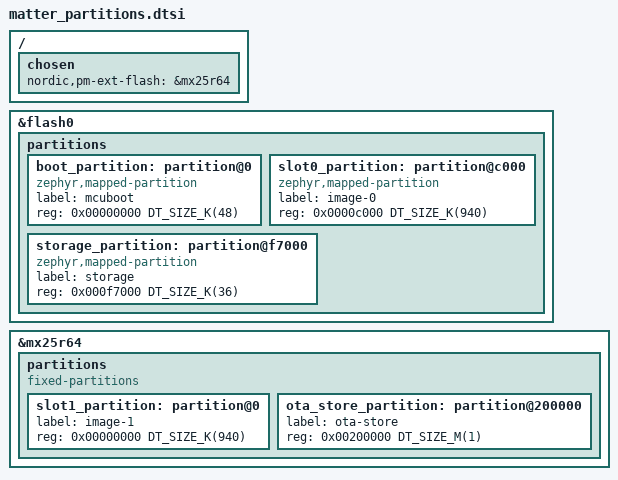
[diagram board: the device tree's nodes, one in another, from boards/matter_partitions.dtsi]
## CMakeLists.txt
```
#
# Cranium firmware, Matter variant: the board as Matter commissioner and Thread border router
# (docs/matter-thread.md). A separate application from firmware/app, with the same version number: VERSION
# here is a link to firmware/app/VERSION.
#
# The Matter commissioner is this project's own (src/matter/): connectedhomeip's controller does not fit next to
# Wi-Fi and the border router in the nRF5340's flash.
#
cmake_minimum_required(VERSION 3.20.0)

find_package(Zephyr REQUIRED HINTS $ENV{ZEPHYR_BASE})
project(cranium_matter)

target_sources(app PRIVATE
  src/main.c
  src/ot_leader.c
  src/matter_shell.c
  src/policy/matter_policy.c
  src/matter/mt_tlv.c
  src/matter/mt_btp.c
  src/matter/mt_msg.c
  src/matter/mt_im.c
  src/matter/mt_pase_msg.c
  src/matter/mt_crypto.c
  src/matter/mt_ble.c
  src/matter/mt_ble_adv.c
  src/matter/mt_commission.c
  src/matter/mt_der.c
  src/matter/mt_cert.c
  src/matter/mt_attest.c
  src/matter/mt_test_paa.c
  src/matter/mt_fabric.c
  src/matter/mt_case_msg.c
  src/matter/mt_controller.c
  src/matter/mt_bdx.c
  src/matter/mt_ota.c
  src/matter/mt_ota_store.c
  src/matter/mt_server.c
  src/matter/mt_identity.c
  src/matter/mt_node.c
  src/matter/mt_csr.c
  src/matter/mt_dev_im.c
  src/matter/mt_peripheral.c
  src/matter/mt_ota_req.c
  src/matter_node.c
  src/matter_selftest.c
)
target_include_directories(app PRIVATE src src/policy src/matter)

# The board's Matter TEST device credentials (DAC, its key, PAI, certification declaration), generated from the
# Matter SDK in the build's SDK at configure time, so that no key is kept in this repository.
set(cranium_test_creds ${CMAKE_CURRENT_BINARY_DIR}/mt_test_credentials.c)
find_package(Python3 REQUIRED COMPONENTS Interpreter)
execute_process(
  COMMAND ${Python3_EXECUTABLE} -I ${CMAKE_CURRENT_LIST_DIR}/scripts/gen_test_credentials.py
          ${ZEPHYR_CONNECTEDHOMEIP_MODULE_DIR} ${cranium_test_creds}
  RESULT_VARIABLE cranium_creds_result)
if(NOT cranium_creds_result EQUAL 0)
  message(FATAL_ERROR "The Matter SDK's test credentials could not be read (scripts/gen_test_credentials.py)")
endif()
target_sources(app PRIVATE ${cranium_test_creds})

if(CONFIG_CRANIUM_MATTER_BORDER_ROUTER)
  target_sources(app PRIVATE src/border_router.c)

  # The border router's platform code for OpenThread: the backbone interface, the UDP and mDNS sockets.
  # Zephyr has it in modules/openthread/platform, but this SDK builds OpenThread's platform from its own list
  # (nrf/modules/openthread/platform), which leaves these out, so this application builds them, patched for this
  # SDK's OpenThread (sdk/patch_sdk.py). src/br/br_unused.c stands in for the parts left out.
  set(ot_platform ${ZEPHYR_BASE}/modules/openthread/platform)
  target_sources(app PRIVATE
    ${ot_platform}/infra_if.c
    ${ot_platform}/udp.c
    ${ot_platform}/mdns_socket.c
    src/br/br_unused.c
  )
  target_include_directories(app PRIVATE
    ${ot_platform}
    ${ZEPHYR_BASE}/subsys/net/ip
    ${ZEPHYR_BASE}/subsys/net/lib/sockets
    ${ZEPHYR_BASE}/subsys/net/lib/dns
    ${ZEPHYR_OPENTHREAD_MODULE_DIR}/src/core
  )
  target_link_libraries(app PRIVATE ot-config)
  # Zephyr's OpenThread start-up code includes the border router's header from here.
  zephyr_include_directories(${ZEPHYR_BASE}/subsys/net/l2/openthread ${ot_platform})
endif()
```

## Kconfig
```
#
# The Matter variant: the board as Matter commissioner and Thread border router (docs/matter-thread.md).
#
mainmenu "Cranium Matter commissioner and Thread border router"

config CRANIUM_THREAD_CHANNEL
	int "Thread channel of a network this board forms"
	range 11 26
	default 25
	help
	  Used only when the board has no Thread network yet and forms one. Keep it away from the Wi-Fi channel:
	  25 is clear of Wi-Fi 1 and 6, 15 of Wi-Fi 11 (src/policy/matter_policy.c, mp_pick_thread_channel()).

config CRANIUM_MATTER_BORDER_ROUTER
	bool "Thread border router with Wi-Fi as the backbone"
	default y if WIFI_NRF70
	depends on OPENTHREAD_ZEPHYR_BORDER_ROUTER
	help
	  Joins the stored Wi-Fi network at start-up (src/border_router.c); Zephyr's OpenThread border router
	  takes it as the backbone once it is up. Wi-Fi credentials are added with the shell's "wifi cred add".

source "Kconfig.zephyr"
```

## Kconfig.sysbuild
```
#
# Sysbuild for the Matter variant: MCUboot, and the network core running Bluetooth and 802.15.4 together.
#

choice BOOTLOADER
	default BOOTLOADER_MCUBOOT
endchoice

config NRF_DEFAULT_IPC_RADIO
	default y

config NETCORE_IPC_RADIO_IEEE802154
	default y

config NETCORE_IPC_RADIO_BT_HCI_IPC
	default y

# The Wi-Fi chip, on the nRF7002 DK only: the border router's backbone.
config WIFI_NRF70
	default y if BOARD_NRF7002DK

config PARTITION_MANAGER
	default n

source "share/sysbuild/Kconfig"
```

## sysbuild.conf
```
#
# Sysbuild settings of the Matter variant (docs/matter-thread.md).
#
SB_CONFIG_MATTER=y
SB_CONFIG_PARTITION_MANAGER=n
SB_CONFIG_BOOTLOADER_MCUBOOT=y
# The team's signing key, as in firmware/app/sysbuild.conf; it stays outside the repository.
SB_CONFIG_BOOT_SIGNATURE_TYPE_ECDSA_P256=y
SB_CONFIG_BOOT_SIGNATURE_KEY_FILE="\$ENV{HOME}/.cranium/mcuboot_signing_key.pem"
SB_CONFIG_MCUBOOT_MODE_SWAP_USING_MOVE=y
# The application image only; the network core is flashed over the debug port.
SB_CONFIG_SECURE_BOOT_NETCORE=n
SB_CONFIG_NETCORE_APP_UPDATE=n
```

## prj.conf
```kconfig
#
# The Matter variant, common to both boards (docs/matter-thread.md). border_router.conf adds Wi-Fi and the
# border router on the nRF7002 DK. The Matter commissioner is this project's own C code (src/matter/), built on
# the PSA crypto API: no connectedhomeip, no mbedTLS X.509.
#

# Bluetooth LE: central for commissioning (BTP over the device's CHIPoBLE service), peripheral for updates.
CONFIG_BT=y
CONFIG_BT_CENTRAL=y
CONFIG_BT_OBSERVER=y
CONFIG_BT_PERIPHERAL=y
CONFIG_BT_GATT_CLIENT=y
CONFIG_BT_GATT_AUTO_DISCOVER_CCC=y
CONFIG_BT_MAX_CONN=2
CONFIG_BT_BUF_ACL_RX_SIZE=251
CONFIG_BT_BUF_ACL_TX_SIZE=251
CONFIG_BT_L2CAP_TX_MTU=247
CONFIG_BT_DEVICE_NAME="Cranium"

# Thread: a full device that forms the network and leads it, with the SRP and DNS-SD server the devices
# register with. OpenThread's heap is the system heap: on its own small one the SRP server starts with no
# domain and refuses every registration.
CONFIG_NETWORKING=y
CONFIG_NET_L2_OPENTHREAD=y
CONFIG_OPENTHREAD_FTD=y
CONFIG_OPENTHREAD_MANUAL_START=y
CONFIG_OPENTHREAD_EXTERNAL_HEAP=y
CONFIG_OPENTHREAD_SRP_SERVER=y
CONFIG_OPENTHREAD_ENABLE_SERVICE=y
CONFIG_OPENTHREAD_DNSSD_SERVER=y
CONFIG_OPENTHREAD_DNS_CLIENT=y
CONFIG_OPENTHREAD_MAX_CHILDREN=10
CONFIG_NET_IPV6=y
CONFIG_NET_UDP=y
CONFIG_NET_SOCKETS=y

# Crypto for the commissioner, through PSA: SPAKE2+ as the prover (PASE), P-256 ECDSA and ECDH (CASE, the
# fabric's certificates, attestation), HKDF, AES-CCM, PBKDF2 and SHA-256.
CONFIG_PSA_CRYPTO_DRIVER_OBERON=y
CONFIG_PSA_WANT_ALG_SPAKE2P_MATTER=y
CONFIG_PSA_WANT_KEY_TYPE_SPAKE2P_KEY_PAIR_IMPORT=y
CONFIG_PSA_WANT_ALG_ECDSA=y
CONFIG_PSA_WANT_ALG_ECDH=y
CONFIG_PSA_WANT_ECC_SECP_R1_256=y
CONFIG_PSA_WANT_KEY_TYPE_ECC_KEY_PAIR_GENERATE=y
CONFIG_PSA_WANT_KEY_TYPE_ECC_KEY_PAIR_IMPORT=y
CONFIG_PSA_WANT_KEY_TYPE_ECC_KEY_PAIR_EXPORT=y
CONFIG_PSA_WANT_KEY_TYPE_ECC_PUBLIC_KEY=y
CONFIG_PSA_WANT_ALG_HKDF=y
CONFIG_PSA_WANT_ALG_HMAC=y
CONFIG_PSA_WANT_ALG_CCM=y
CONFIG_PSA_WANT_KEY_TYPE_AES=y
CONFIG_PSA_WANT_ALG_PBKDF2_HMAC=y
CONFIG_PSA_WANT_ALG_SHA_256=y
# This board as a device: the PASE verifier (w0 || L from the passcode).
CONFIG_PSA_WANT_KEY_TYPE_SPAKE2P_PUBLIC_KEY=y
CONFIG_PSA_WANT_KEY_TYPE_SPAKE2P_KEY_PAIR_DERIVE=y
CONFIG_PSA_WANT_KEY_TYPE_SPAKE2P_KEY_PAIR_EXPORT=y

# Its own update over Matter: the image goes into MCUboot's second slot.
CONFIG_FLASH_PAGE_LAYOUT=y
CONFIG_STREAM_FLASH=y
CONFIG_IMG_MANAGER=y
CONFIG_MCUBOOT_IMG_MANAGER=y

# The fabric's root key and the board's operational key are persistent PSA keys, kept by trusted storage in
# settings. Without a hardware unique key in use, their storage key comes from a hash of the key ID: not
# protected against someone reading the flash.
CONFIG_MBEDTLS_PSA_CRYPTO_STORAGE_C=y
CONFIG_TRUSTED_STORAGE=y
CONFIG_TRUSTED_STORAGE_BACKEND_AEAD_KEY_HASH_UID=y
CONFIG_TRUSTED_STORAGE_STORAGE_BACKEND_SETTINGS=y

# Storage, console and shell.
CONFIG_SETTINGS=y
CONFIG_SETTINGS_NVS=y
CONFIG_FLASH=y
CONFIG_FLASH_MAP=y
CONFIG_NVS=y
CONFIG_SHELL=y
# Long enough for tools/matter_ota_upload.py's chunks of an OTA image.
CONFIG_SHELL_CMD_BUFF_SIZE=600
CONFIG_LOG=y
# Warnings and errors only from the stacks; this project's modules log their own progress.
CONFIG_LOG_DEFAULT_LEVEL=2
CONFIG_MAIN_STACK_SIZE=4096
CONFIG_SYSTEM_WORKQUEUE_STACK_SIZE=4096
CONFIG_HEAP_MEM_POOL_SIZE=32768
CONFIG_REBOOT=y
CONFIG_THREAD_NAME=y
CONFIG_MPU_STACK_GUARD=y
CONFIG_DK_LIBRARY=y
```

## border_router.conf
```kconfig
#
# The border router: Wi-Fi station on the nRF7002 DK, and Zephyr's OpenThread border router with Wi-Fi as its
# backbone. Added to the application by sysbuild.cmake when SB_CONFIG_CRANIUM_BORDER_ROUTER is on
# (border_router_sysbuild.conf). Matter itself stays on Thread (CHIP_WIFI off): Wi-Fi is the border router's link,
# not a Matter transport.
#
# It does not fit yet: docs/matter-thread.md, "Memory, per board".
#
CONFIG_CHIP_WIFI=n
CONFIG_WIFI=y
CONFIG_WIFI_NRF70=y
CONFIG_WIFI_NM_WPA_SUPPLICANT=y
CONFIG_NET_L2_ETHERNET=y
CONFIG_WIFI_CREDENTIALS=y
CONFIG_WIFI_CREDENTIALS_SHELL=y
CONFIG_NET_L2_WIFI_SHELL=y

# IP on both sides, routing between them.
CONFIG_NET_IPV6=y
CONFIG_NET_IPV4=y
CONFIG_NET_UDP=y
CONFIG_NET_TCP=y
CONFIG_NET_SOCKETS=y
CONFIG_NET_DHCPV4=y
CONFIG_NET_MGMT_EVENT=y
CONFIG_NET_MGMT_EVENT_INFO=y
CONFIG_NET_CONNECTION_MANAGER=y
CONFIG_NET_ROUTE_MCAST=y
CONFIG_NET_SOCKETS_SERVICE=y
CONFIG_NET_CONTEXT_RECV_PKTINFO=y
CONFIG_NET_CONTEXT_RECV_HOPLIMIT=y
CONFIG_NET_IPV6_NBR_CACHE=y
CONFIG_NET_MAX_MCAST_ROUTES=10
CONFIG_NET_SOCKETS_INET_RAW=y

# Zephyr's OpenThread border router, cut to what a home network needs: routing between Thread and Wi-Fi, the SRP
# advertising proxy with mDNS on Wi-Fi (a laptop finds the Matter devices), and the border agent, which Zephyr's
# border router code requires. Left out to save memory: NAT64, TREL, DHCPv6 prefix delegation, upstream DNS.
CONFIG_OPENTHREAD_ZEPHYR_BORDER_ROUTER=y
CONFIG_OPENTHREAD_ZEPHYR_BORDER_ROUTER_VENDOR_NAME="Cranium"
CONFIG_OPENTHREAD_ZEPHYR_BORDER_ROUTER_BASE_SERVICE_NAME="Cranium-BorderRouter"
CONFIG_OPENTHREAD_ZEPHYR_BORDER_ROUTER_MODEL_NAME="Cranium"
CONFIG_OPENTHREAD_ZEPHYR_BORDER_ROUTER_IPV4=n
CONFIG_OPENTHREAD_ZEPHYR_BORDER_ROUTER_NAT64_TRANSLATOR=n
CONFIG_OPENTHREAD_BORDER_ROUTER=y
CONFIG_OPENTHREAD_BORDER_ROUTING=y
# Needed by OpenThread's routing manager in this SDK, which does not build without it.
CONFIG_OPENTHREAD_BORDER_ROUTING_COUNTERS=y
CONFIG_OPENTHREAD_BORDER_AGENT=y
CONFIG_OPENTHREAD_BORDER_AGENT_ID=y
CONFIG_OPENTHREAD_BORDER_AGENT_MESHCOP_SERVICE=y
# The border agent's DTLS with EC-JPAKE comes with OpenThread's own (Thread-level) commissioner, as in Zephyr's
# border router sample; it also lets the border router admit Thread joiners.
CONFIG_OPENTHREAD_COMMISSIONER=y
CONFIG_OPENTHREAD_NETDATA_PUBLISHER=y
CONFIG_OPENTHREAD_BACKBONE_ROUTER=y
CONFIG_OPENTHREAD_BACKBONE_ROUTER_MULTICAST_ROUTING=y
CONFIG_OPENTHREAD_SRP_ADV_PROXY=y
CONFIG_OPENTHREAD_DNSSD_DISCOVERY_PROXY=y
CONFIG_OPENTHREAD_MULTICAST_DNS=y
CONFIG_OPENTHREAD_PLATFORM_UDP=y
CONFIG_OPENTHREAD_INTERFACE_EARLY_UP=y
CONFIG_OPENTHREAD_SLAAC=y
CONFIG_OPENTHREAD_MAX_STATECHANGE_HANDLERS=3
CONFIG_OPENTHREAD_DUA=y
CONFIG_OPENTHREAD_MLR=y
CONFIG_OPENTHREAD_IP6_FRAGM=y
CONFIG_OPENTHREAD_ECDSA=y
CONFIG_OPENTHREAD_TREL=n
CONFIG_OPENTHREAD_NAT64_TRANSLATOR=n

# Room in flash: the supplicant logs errors only and leaves out WEP, which no network should still use.
CONFIG_WIFI_NM_WPA_SUPPLICANT_LOG_LEVEL_ERR=y
CONFIG_WIFI_NM_WPA_SUPPLICANT_WEP=n
```

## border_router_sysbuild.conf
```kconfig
#
# The Matter variant with the Thread border router on Wi-Fi (nRF7002 DK only):
#   west build -b nrf7002dk/nrf5340/cpuapp --sysbuild firmware/matter -- -DSB_EXTRA_CONF_FILE=border_router_sysbuild.conf
# It does not fit in the nRF5340's flash yet: docs/matter-thread.md, "Memory, per board".
#
SB_CONFIG_CRANIUM_BORDER_ROUTER=y
```

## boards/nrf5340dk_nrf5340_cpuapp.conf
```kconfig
# The nRF5340 DK has no Wi-Fi: the board leads its Thread network with no backbone.
CONFIG_NORDIC_QSPI_NOR=y
CONFIG_NORDIC_QSPI_NOR_FLASH_LAYOUT_PAGE_SIZE=4096
CONFIG_NORDIC_QSPI_NOR_STACK_WRITE_BUFFER_SIZE=16
```

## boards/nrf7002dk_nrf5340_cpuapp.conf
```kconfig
#
# The nRF7002 DK: commissioner, Thread leader and, from border_router.conf (on by default here), the border router
# on Wi-Fi.
#
# External flash on SPI, as in the main image.
CONFIG_SPI=y
CONFIG_SPI_NOR=y
CONFIG_SPI_NOR_SFDP_DEVICETREE=y
CONFIG_SPI_NOR_FLASH_LAYOUT_PAGE_SIZE=4096
```

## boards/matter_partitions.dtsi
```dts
/*
 * The Matter variant's flash layout, the same for the application and MCUboot, on both boards
 * (docs/matter-thread.md, "The build"). It is not one of firmware/app/flash_layouts.json: a board running the
 * main image refuses this one as an update, and the other way round.
 *
 * Internal flash (1 MiB): MCUboot 48 KiB, the application 940 KiB, settings 36 KiB (Thread dataset, the Matter
 * fabric and keys, Wi-Fi credentials). External flash: the second image slot, and from 2 MB the OTA store (1 MB). MCUboot has 48 KiB because on the
 * nRF7002 DK its SPI flash driver does not fit in 32 KiB.
 */

/delete-node/ &boot_partition;
/delete-node/ &slot0_partition;
/delete-node/ &slot1_partition;
/delete-node/ &storage_partition;

&flash0 {
	partitions {
		boot_partition: partition@0 {
			compatible = "zephyr,mapped-partition";
			label = "mcuboot";
			reg = <0x00000000 DT_SIZE_K(48)>;
		};

		slot0_partition: partition@c000 {
			compatible = "zephyr,mapped-partition";
			label = "image-0";
			reg = <0x0000c000 DT_SIZE_K(940)>;
		};

		storage_partition: partition@f7000 {
			compatible = "zephyr,mapped-partition";
			label = "storage";
			reg = <0x000f7000 DT_SIZE_K(36)>;
		};
	};
};

/ {
	chosen {
		nordic,pm-ext-flash = &mx25r64;
	};
};

&mx25r64 {
	status = "okay";

	partitions {
		compatible = "fixed-partitions";
		#address-cells = <1>;
		#size-cells = <1>;

		slot1_partition: partition@0 {
			label = "image-1";
			reg = <0x00000000 DT_SIZE_K(940)>;
		};

		/* The image this board offers its Matter devices as OTA provider (src/matter/mt_ota_store.c). */
		ota_store_partition: partition@200000 {
			label = "ota-store";
			reg = <0x00200000 DT_SIZE_M(1)>;
		};
	};
};
```

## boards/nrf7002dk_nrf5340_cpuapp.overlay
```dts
/*
 * The Matter variant on this board: its flash layout, and the inter-core link at the highest priority so that
 * 802.15.4 frames from the network core are not held up.
 */
#include "matter_partitions.dtsi"
#include "nrf70_patch_partitions.dtsi"
#include <zephyr/dt-bindings/ipc_service/static_vrings.h>

&ipc0 {
	zephyr,priority = <0 PRIO_COOP>;
};
```

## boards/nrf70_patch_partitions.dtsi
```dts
/*
 * The nRF70's firmware patches in the DK's external flash, after the second application slot: 88 KB of the
 * application's internal flash freed. MCUboot treats them as its second image (image 1: slot2 holds them, slot3
 * takes an update), signed with the same key.
 *
 * Two names for slot 2, on purpose. MCUboot reads the image header at the start of slot2_partition. The driver
 * (nrf/subsys/net/lib/nrf70_fw_ext) reads the patches from offset 0 of nrf70_fw_partition, and the SDK's build
 * places them, before signing, at the start of nrf70_wifi_fw_partition: both must begin after the 0x200-byte
 * MCUboot header (CONFIG_ROM_START_OFFSET). With one node at 0xeb000 the signed image's header landed at 0xeae00,
 * MCUboot found no valid image 1 and refused to boot anything ("Unable to find bootable image").
 */
&mx25r64 {
	partitions {
		slot2_partition: partition@eb000 {
			label = "image-2";
			reg = <0x000eb000 DT_SIZE_K(128)>;
		};

		/* Inside slot2_partition, after the MCUboot header: the patches themselves. */
		nrf70_wifi_fw_partition: nrf70_fw_partition: partition@eb200 {
			label = "nrf70-fw";
			reg = <0x000eb200 (DT_SIZE_K(128) - 0x200)>;
		};

		slot3_partition: partition@10b000 {
			label = "image-3";
			reg = <0x0010b000 DT_SIZE_K(128)>;
		};
	};
};
```

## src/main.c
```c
/*
 * The Matter variant's start-up (docs/matter-thread.md): the board leads a Thread network with an SRP server,
 * joins Wi-Fi as the border router's backbone, and runs this project's own Matter commissioner (src/matter/).
 * Becoming leader is retried with a growing delay that never gives up (src/policy/matter_policy.c).
 */
#include <zephyr/bluetooth/bluetooth.h>
#include <zephyr/kernel.h>
#include <zephyr/logging/log.h>
#include <zephyr/settings/settings.h>

#include "matter_policy.h"
#include "mt_controller.h"
#include "mt_fabric.h"
#include "matter_node.h"
#include "ot_leader.h"
#if defined(CONFIG_CRANIUM_MATTER_BORDER_ROUTER)
#include "border_router.h"
#endif

LOG_MODULE_REGISTER(main, LOG_LEVEL_INF);

static void thread_up(struct k_work *work);
static K_WORK_DELAYABLE_DEFINE(thread_work, thread_up);
static uint32_t thread_attempt;

static void thread_up(struct k_work *work)
{
	ARG_UNUSED(work);

	if (ot_leader_start() == 0) {
		LOG_INF("Thread up (role %s), SRP server on", ot_leader_role());
		/* The fabric, then sessions to the devices already on it. */
		if (mt_fabric_init() != 0 || mt_ctl_init() != 0) {
			LOG_ERR("the Matter fabric could not start");
			return;
		}
		mt_ctl_reconnect_all();
		/* and as a device a phone can add */
		matter_node_start();
		return;
	}
	uint32_t ms = mp_backoff_ms(thread_attempt++, MP_RETRY_FIRST_MS, MP_RETRY_CAP_MS);

	LOG_WRN("Thread start failed, again in %u s", ms / 1000);
	k_work_schedule(&thread_work, K_MSEC(ms));
}

int main(void)
{
	LOG_INF("Cranium Matter commissioner and Thread border router");
	if (settings_subsys_init() != 0) {
		LOG_ERR("settings could not start: the fabric cannot be kept");
	}

	int err = bt_enable(NULL);

	if (err != 0) {
		LOG_ERR("Bluetooth did not start: %d", err);
	}
#if defined(CONFIG_CRANIUM_MATTER_BORDER_ROUTER)
	(void)border_router_start();
#endif
	k_work_schedule(&thread_work, K_NO_WAIT);
	return 0;
}
```

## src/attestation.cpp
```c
/*
 * See attestation.h.
 */
#include "attestation.h"

#include <credentials/attestation_verifier/DacOnlyPartialAttestationVerifier.h>
#include <credentials/attestation_verifier/DefaultDeviceAttestationVerifier.h>
#include <lib/support/logging/CHIPLogging.h>

namespace nrf {
namespace controller {

chip::Credentials::DeviceAttestationVerifier * GetBringupDacVerifier()
{
#if defined(CONFIG_CRANIUM_MATTER_ATTESTATION_PARTIAL)
    static chip::Credentials::PartialDACVerifier sVerifier;
    chip::Credentials::SetDeviceAttestationVerifier(&sVerifier);
    ChipLogProgress(Controller, "Attestation: partial (no PAA chain, no certification declaration): development only");
    return &sVerifier;
#else
    const chip::Credentials::AttestationTrustStore * trustStore = chip::Credentials::GetTestAttestationTrustStore();
    chip::Credentials::DeviceAttestationVerifier * verifier = chip::Credentials::GetDefaultDACVerifier(trustStore);
    chip::Credentials::SetDeviceAttestationVerifier(verifier);
    ChipLogProgress(Controller, "Attestation: Matter test PAA only (vendor 0xFFF1 test devices)");
    return verifier;
#endif
}

} // namespace controller
} // namespace nrf
```

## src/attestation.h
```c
/*
 * The device attestation verifier the commissioner uses to check a new device's certificates (its DAC, PAI and
 * certification declaration).
 *
 * Two modes, chosen with CONFIG_CRANIUM_MATTER_ATTESTATION_PARTIAL:
 *   - partial (default during development): the DAC and PAI are parsed and their signatures checked, but the
 *     chain is not taken up to a trusted PAA and the certification declaration is not checked. Retail devices,
 *     whose PAAs are not built in, pass.
 *   - test trust store: only devices with Matter test certificates (vendor 0xFFF1, the test PAA) pass.
 * A product needs a third mode: the full check against the production PAAs from the Distributed Compliance Ledger.
 */
#pragma once

#include <credentials/attestation_verifier/DeviceAttestationVerifier.h>

namespace nrf {
namespace controller {

/* Installs the verifier as the stack's default and returns it. */
chip::Credentials::DeviceAttestationVerifier * GetBringupDacVerifier();

} // namespace controller
} // namespace nrf
```

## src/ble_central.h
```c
/*
 * BLE *central* role for Matter commissioning on Zephyr.
 *
 * The stock NCS Zephyr BLEManagerImpl implements only the peripheral/accessory
 * role; a commissioner must be GATT *client*. This object supplies the missing
 * glue: scan-by-discriminator, connect, GATT-discover the CHIPoBLE service,
 * subscribe to TX (indications), write RX, and bridge GATT events back to the
 * CHIP BleLayer. A small patch to the SDK BLEManagerImpl (patches/0001) wires
 * BleLayer::Init's connDelegate to BleCentral and forwards the three central
 * BlePlatformDelegate ops here. See firmware/matter/sdk/patch_sdk.py
 * ("Zephyr Platform BLE Central Glue Layer") for the verified bt_* contract.
 */

/*
 * In plain English:
 *   This is the header (the "table of contents") for the Bluetooth code that lets
 *   our hub PAIR with a brand-new smart device. Matter is a smart-home standard
 *   that lets gadgets from different brands work together; our hub is the
 *   "commissioner" that adds and controls those gadgets. To first reach a new
 *   gadget we use BLE (Bluetooth Low Energy, short-range Bluetooth). In Bluetooth
 *   terms our hub is the "central" (the scanner/connector, like a phone) and the
 *   gadget is the "peripheral" (the advertiser). Nordic's ready-made SDK only knows
 *   how to be the peripheral, so we had to write the central side ourselves — that
 *   is the BleCentral class declared here. It scans the airwaves, connects, reads
 *   the gadget's menu of data slots, subscribes for incoming messages, and passes
 *   everything up to the Matter software.
 */
#pragma once

#include <ble/Ble.h>
#include <ble/BleConnectionDelegate.h>
#include <ble/BleLayer.h>
#include <ble/BleUUID.h>
#include <lib/core/CHIPError.h>
#include <setup_payload/SetupPayload.h>
#include <system/SystemPacketBuffer.h>

#include <zephyr/bluetooth/conn.h>
#include <zephyr/bluetooth/gatt.h>

namespace nrf {
namespace controller {

// CHIPoBLE service + characteristic UUIDs (16-bit service 0xFFF6; 128-bit chars).
// Values mirror the Zephyr BLEManagerImpl declarations (already in BT byte order).
// The "name tag" (UUID) that every Matter device broadcasts over Bluetooth during
// setup. CHIPoBLE / service 0xFFF6 is the Bluetooth service a Matter device advertises;
// when we scan, we look for exactly this number to know a device is a Matter gadget.
inline constexpr uint16_t kCHIPoBLEServiceUuid16 = 0xFFF6;

/**
 * Singleton implementing BLE central for commissioning. Also a BleConnectionDelegate
 * (installed into BleLayer by the BLEManagerImpl patch via the 4-arg BleLayer::Init).
 */
// The one-and-only Bluetooth-central object for the whole program (a "singleton":
// exactly one instance exists). It also plays the role Matter expects for making new
// Bluetooth connections during pairing, so Matter can ask it to reach a new device.
class BleCentral final : public chip::Ble::BleConnectionDelegate
{
public:
    // Get the single shared BleCentral object (creates it the first time it's asked for).
    static BleCentral & Instance();

    /// Register the central bt_conn_cb / scan callbacks. Called once at stack init.
    // One-time setup: tell Bluetooth to call our functions when scans find devices and
    // when connections come and go. Run once when the Bluetooth stack starts up.
    CHIP_ERROR Init();

    // ===== chip::Ble::BleConnectionDelegate =====
    // Matter calls this to say "please find and connect to a new device that is
    // broadcasting this discriminator (its ID number, e.g. 3321)." Kicks off scanning.
    void NewConnection(chip::Ble::BleLayer * bleLayer, void * appState,
                       const chip::SetupDiscriminator & connDiscriminator) override;
    // Overload for when Matter already has a live Bluetooth connection object in hand
    // and just wants us to adopt/use it, rather than scanning for a device first.
    void NewConnection(chip::Ble::BleLayer * bleLayer, void * appState, BLE_CONNECTION_OBJECT connObj) override;
    // Matter calls this to abort an in-progress connection attempt (stop scanning /
    // drop the pending connection), e.g. if pairing was cancelled or timed out.
    CHIP_ERROR CancelConnection() override;

    // ===== central BlePlatformDelegate ops, forwarded from the patched BLEManagerImpl =====
    // Turn ON incoming messages from the device on its TX slot (flip the CCC switch)
    // so the device can push its handshake replies to us. Matter asks for this once
    // the connection is ready. svcId/charId identify which service+slot to subscribe to.
    CHIP_ERROR SubscribeCharacteristic(BLE_CONNECTION_OBJECT conId, const chip::Ble::ChipBleUUID * svcId,
                                       const chip::Ble::ChipBleUUID * charId);
    // Turn OFF those incoming messages again (the reverse of Subscribe), used at teardown.
    CHIP_ERROR UnsubscribeCharacteristic(BLE_CONNECTION_OBJECT conId, const chip::Ble::ChipBleUUID * svcId,
                                         const chip::Ble::ChipBleUUID * charId);
    // Send one chunk of Matter's handshake data to the device by writing it into the
    // device's RX slot (the slot we write to). Matter calls this to talk to the device.
    CHIP_ERROR SendWriteRequest(BLE_CONNECTION_OBJECT conId, const chip::Ble::ChipBleUUID * svcId,
                                const chip::Ble::ChipBleUUID * charId, chip::System::PacketBufferHandle pBuf);

private:
    // Private constructor: nobody can build a BleCentral directly; use Instance() above.
    BleCentral() = default;

public:
    // Per-connection GATT handle table (discovered before subscribe/write).
    // Everything we need to remember about ONE connected device. GATT is Bluetooth's
    // menu of data slots a device exposes; a "handle" is the numeric address of a slot.
    // We look these addresses up (discovery) right after connecting, then reuse them.
    struct ConnState
    {
        // The Bluetooth connection this state belongs to (null = empty/unused slot).
        bt_conn * conn               = nullptr;
        // Address of the slot we WRITE to, to send data to the device (the RX slot).
        uint16_t rxValueHandle       = 0; // CHIPoBLE C1 (RX): write target
        // Address of the slot the device sends data back on, which we subscribe to (TX).
        uint16_t txValueHandle       = 0; // CHIPoBLE C2 (TX): indications
        // Address of the little on/off switch (CCC) that enables those incoming messages.
        uint16_t txCccHandle         = 0;
        // True while this record is holding a live connection (marks the slot as taken).
        bool inUse                   = false;
        // Bluetooth's bookkeeping for our "please push me messages" subscription.
        bt_gatt_subscribe_params sub = {};
        // Bluetooth's bookkeeping for walking the device's menu of slots (discovery).
        bt_gatt_discover_params disc = {};
        // Bluetooth's bookkeeping for an in-flight write to the device.
        bt_gatt_write_params write   = {};
    };
    // Find (or set up) the ConnState record for a given Bluetooth connection.
    ConnState & Slot(const bt_conn * conn);

    // App state (BleLayer) passed to the OnConnection* callbacks. Exposed so the
    // file-static connect/discovery helpers in the .cpp can forward it.
    // Hand back the opaque "context" pointer Matter gave us, so helper code in the .cpp
    // can pass it along when reporting connection results back up to Matter.
    void * AppState() const { return mAppState; }

    // BT-RX-thread callbacks marshal to the CHIP thread via PlatformMgr().
    // IMPORTANT: every callback below is fired by the Bluetooth stack on its own
    // (BT-RX) thread, NOT the Matter thread. Each one hands the work over to the single
    // Matter thread (marshalling) before touching Matter code, because Matter logic must
    // only ever run on that one thread.
    // Fires when a scan finds a nearby advertising device; we check if it's the one we want.
    static void ScanRecvCb(const bt_le_scan_recv_info * info, net_buf_simple * buf);
    // Fires when a connection attempt finishes (err says success or failure).
    static void CentralConnectedCb(bt_conn * conn, uint8_t err);
    // Fires when a device disconnects (reason says why); we clean up its state.
    static void CentralDisconnectedCb(bt_conn * conn, uint8_t reason);
    // Fires repeatedly while walking the device's menu of slots (discovery), once per
    // slot found, so we can record the RX/TX/CCC handle addresses we need.
    static uint8_t GattDiscoverCb(bt_conn * conn, const bt_gatt_attr * attr, bt_gatt_discover_params * params);
    // Fires when the device pushes us a message on its TX slot (an incoming notification/
    // indication); we forward that data up to Matter.
    static uint8_t GattNotifyCb(bt_conn * conn, bt_gatt_subscribe_params * params, const void * data, uint16_t length);
    // Fires once the "please push me messages" subscription is confirmed set up.
    static void GattSubscribedCb(bt_conn * conn, uint8_t err, bt_gatt_subscribe_params * params);
    // Fires once a write we sent to the device's RX slot has completed.
    static void GattWriteCb(bt_conn * conn, uint8_t err, bt_gatt_write_params * params);

private:
    // Matter's Bluetooth layer we report events to (the software above us). Null until set.
    chip::Ble::BleLayer * mBleLayer  = nullptr;
    // Opaque context pointer Matter gave us to hand back with connection results.
    void * mAppState                 = nullptr;
    // The ID number (discriminator) of the specific device we're currently hunting for.
    chip::SetupDiscriminator mTargetDiscriminator;
    // True while we're actively scanning the airwaves for that device.
    bool mScanning                   = false;
    // The connection we've started but not yet finished setting up (null if none).
    bt_conn * mPendingConn           = nullptr;
};

} // namespace controller
} // namespace nrf
```

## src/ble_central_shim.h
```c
/*
 * ble_central_shim.h — minimal forwarding surface used by the PATCHED SDK
 * Zephyr BLEManagerImpl.cpp (patches/0001) so it can hand the BLE-central role
 * to the in-project implementation without depending on the full ble_central.h.
 * Implemented in src/ble_central.cpp. Visible to the chip module via the
 * zephyr_include_directories() line in CMakeLists.txt.
 *
 * In plain English:
 * This is a tiny "bridge" header. Nordic's Bluetooth code (BLEManagerImpl.cpp,
 * which we've patched) normally only knows how to be the gadget/advertiser side
 * of Bluetooth. To pair brand-new smart devices, THIS hub needs to be the
 * scanner/connector side instead (BLE Central — the "phone" role). Our own code
 * that does that lives in a C++ class called BleCentral. But the patched Nordic
 * file shouldn't have to know about that whole class; it just needs a few simple
 * "do this for me" entry points. This file declares exactly those few plain
 * functions (connect, subscribe, unsubscribe, write). The Nordic file calls them,
 * and behind the scenes they forward the work to our BleCentral implementation in
 * ble_central.cpp. Keeping the surface this small avoids tangling the two files
 * together.
 */
#pragma once

// The "delegate" interface (a helper object Matter calls to open BLE connections)
// that we hand back below.
#include <ble/BleConnectionDelegate.h>
// Matter's Bluetooth UUID type — a UUID names a Bluetooth service or data slot.
#include <ble/BleUUID.h>
// Matter's error/status type (CHIP_ERROR) returned by the functions below.
#include <lib/core/CHIPError.h>
// Matter's packet buffer — a chunk of bytes to send over Bluetooth.
#include <system/SystemPacketBuffer.h>
// Zephyr's Bluetooth connection type (bt_conn) — a live link to one device.
#include <zephyr/bluetooth/conn.h>

// Everything here lives under nrf::controller, this project's own namespace,
// so these helper names don't collide with SDK names.
namespace nrf {
namespace controller {

/// The BleConnectionDelegate installed into BleLayer (4-arg BleLayer::Init).
// In plain English: hand back the single object that knows how to make our hub
// act as the scanner/connector (BLE Central) so it can reach a brand-new device.
// Matter's Bluetooth layer (BleLayer) is told to use this object at startup, and
// calls into it whenever it needs to open a Bluetooth link to a device we're pairing.
chip::Ble::BleConnectionDelegate * BleCentralConnectionDelegate();

/// Central GATT-client ops forwarded from BLEManagerImpl's (formerly stubbed) methods.
// The next three are the actual "do this over Bluetooth" actions the patched
// Nordic file forwards to us. GATT is Bluetooth's menu of data slots on a device
// (services -> characteristics). "svcId" names a service; "charId" names one data
// slot (characteristic) inside it; "conn" is the live link to that device.

// Turn ON receiving pushed messages from the device on a given data slot
// (subscribe = flip the device's "you may push messages to me" switch, its CCC).
// Used so the device can send its handshake replies back to us. Returns a status.
CHIP_ERROR BleCentralSubscribe(bt_conn * conn, const chip::Ble::ChipBleUUID * svcId,
                               const chip::Ble::ChipBleUUID * charId);
// The reverse: stop receiving pushed messages from that data slot (unsubscribe).
// Used when tearing the Bluetooth link down. Returns a status.
CHIP_ERROR BleCentralUnsubscribe(bt_conn * conn, const chip::Ble::ChipBleUUID * svcId,
                                 const chip::Ble::ChipBleUUID * charId);
// Send bytes TO the device by writing them into one of its data slots.
// "pBuf" holds the bytes to send (e.g. a piece of the pairing handshake).
// Returns a status.
CHIP_ERROR BleCentralWrite(bt_conn * conn, const chip::Ble::ChipBleUUID * svcId,
                           const chip::Ble::ChipBleUUID * charId, chip::System::PacketBufferHandle pBuf);

} // namespace controller
} // namespace nrf
```

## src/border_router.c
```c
/*
 * See border_router.h.
 */
#include "border_router.h"

#include <zephyr/kernel.h>
#include <zephyr/logging/log.h>
#include <zephyr/net/net_if.h>
#include <zephyr/net/net_mgmt.h>
#include <zephyr/net/wifi_mgmt.h>
#include <zephyr/net/wifi_credentials.h>

#include "matter_policy.h"
#include "matter_node.h"

LOG_MODULE_REGISTER(border_router, LOG_LEVEL_INF);

static struct net_mgmt_event_callback wifi_cb;
static uint8_t wifi_channel;

static void check_channel(struct net_if *iface)
{
	struct wifi_iface_status status = {0};

	if (net_mgmt(NET_REQUEST_WIFI_IFACE_STATUS, iface, &status, sizeof(status)) != 0) {
		return;
	}
	wifi_channel = (status.band == WIFI_FREQ_BAND_2_4_GHZ && status.channel > 0 && status.channel <= 14)
			       ? (uint8_t)status.channel
			       : 0;
	LOG_INF("Wi-Fi joined, channel %d: border router backbone up", status.channel);
	if (!mp_thread_channel_clear(CONFIG_CRANIUM_THREAD_CHANNEL, wifi_channel)) {
		LOG_WRN("Thread channel %d overlaps Wi-Fi channel %u; %u would be clear (CONFIG_CRANIUM_THREAD_CHANNEL)",
			CONFIG_CRANIUM_THREAD_CHANNEL, wifi_channel, mp_pick_thread_channel(wifi_channel));
	}
}

static void wifi_event(struct net_mgmt_event_callback *cb, uint64_t event, struct net_if *iface)
{
	ARG_UNUSED(cb);

	if (event == NET_EVENT_WIFI_CONNECT_RESULT) {
		const struct wifi_status *status = (const struct wifi_status *)cb->info;

		if (status != NULL && status->status != 0) {
			LOG_WRN("Wi-Fi join failed (%d); the supplicant keeps trying", status->status);
			return;
		}
		check_channel(iface);
		matter_node_dnssd_update();
	} else if (event == NET_EVENT_WIFI_DISCONNECT_RESULT) {
		wifi_channel = 0;
		LOG_WRN("Wi-Fi lost: Thread keeps running, the backbone is down");
	}
}

int border_router_start(void)
{
	struct net_if *iface = net_if_get_first_wifi();

	if (iface == NULL) {
		LOG_ERR("no Wi-Fi interface");
		return -ENODEV;
	}
	net_mgmt_init_event_callback(&wifi_cb, wifi_event,
				     NET_EVENT_WIFI_CONNECT_RESULT | NET_EVENT_WIFI_DISCONNECT_RESULT);
	net_mgmt_add_event_callback(&wifi_cb);

	if (wifi_credentials_is_empty()) {
		LOG_WRN("no Wi-Fi network stored: add one with \"wifi cred add\", then restart");
		return 0;
	}
	int err = net_mgmt(NET_REQUEST_WIFI_CONNECT_STORED, iface, NULL, 0);

	if (err != 0) {
		LOG_ERR("Wi-Fi join could not start: %d", err);
	}
	return err;
}

uint8_t border_router_wifi_channel(void)
{
	return wifi_channel;
}
```

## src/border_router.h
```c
/*
 * The Wi-Fi side of the Thread border router (nRF7002 DK): joins the stored Wi-Fi network, and says when the
 * Thread channel is too close to the Wi-Fi channel. Zephyr's OpenThread border router starts by itself once the
 * Wi-Fi interface is up and takes it as the backbone.
 */
#pragma once

#include <stdint.h>

#ifdef __cplusplus
extern "C" {
#endif

/* Starts joining the Wi-Fi network stored with "wifi cred add". 0, or a negative errno. */
int border_router_start(void);

/* The 2.4 GHz Wi-Fi channel in use, 0 when there is none (not joined, or 5 GHz). */
uint8_t border_router_wifi_channel(void);

#ifdef __cplusplus
}
#endif
```

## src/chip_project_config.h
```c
/*
 * CHIP project config for the on-device commissioner.
 * Pulled in via CONFIG_CHIP_PROJECT_CONFIG.
 *
 * In plain English: This is a small settings file that the Matter software (CHIP =
 * the open-source code that implements the Matter smart-home standard) reads at
 * build time to know which optional features to switch on. Most settings are
 * already chosen for us by Nordic's SDK (the nRF Connect SDK, or "NCS", the vendor
 * toolkit this firmware is built with). If we set one of those again here, the
 * build would error out complaining it was defined twice. So this file only adds
 * the couple of settings NCS leaves off — the ones that turn this chip into a
 * "commissioner" (the hub/brain that adds and controls smart devices), because
 * Nordic normally ships firmware for the devices being controlled, not the hub.
 *
 * IMPORTANT: the nrfconnect platform config (CHIPDevicePlatformConfig.h) already
 * #defines almost everything from Kconfig (VID/PID, ENABLE_THREAD, ENABLE_CHIPOBLE,
 * ENABLE_THREAD_SRP_CLIENT/DNS_CLIENT, fabrics, read-client, ...). Redefining any
 * of those here is a -Werror redefinition. The ONE thing NCS does not set — because
 * it ships accessory-only — is the commissioner/controller enable. That is all we add.
 */

// Ensures this header is included only once per build, even if referenced multiple
// times, so its settings aren't defined twice.
#pragma once

// This single switch enables all the "hub" code — the parts that let this chip
// add new smart devices to the network and control them (the commissioner role).
// Turn on the on-device commissioner/controller code paths.
#define CHIP_DEVICE_CONFIG_ENABLE_COMMISSIONER 1

// How many devices this hub can be actively setting up at the same moment. We set
// it to 2 (very small) on purpose. The comment below explains why: the standard
// default of 64 is meant for a hub running on a full computer with lots of memory.
// On this tiny chip, reserving room for 64 simultaneous setups would eat far more
// memory (SRAM = the chip's fast working memory) than the chip even has. This hub
// only pairs one device at a time, so a tiny number is plenty.
//
// Correction to the wording just above: 124 KB does NOT exceed the chip's 256 KB of
// SRAM (it is under half of it). The real problem is that 124 KB is an unacceptably
// LARGE FRACTION of that 256 KB budget — memory this hub needs for everything else —
// not that it is more memory than the chip physically has.
//
// Plain-English gloss for the terse developer note below: "chip-tool" is Matter's
// commissioner app that runs on a full PC (which has gigabytes of memory to spare).
// "DeviceCommissioner" is the software object that runs the pairing process.
// "ObjectPool<CommissioneeDeviceProxy, N>" just means it pre-reserves memory for N
// devices-being-paired up front — so N=64 pre-reserves a big chunk of RAM even when
// only one device is ever paired at a time.
// CRITICAL for RAM: the upstream default is 64 (a host commissioner like chip-tool).
// The DeviceCommissioner allocates ObjectPool<CommissioneeDeviceProxy, N>, and at
// N=64 that pool alone is ~124 KB of SRAM — a large share of the RAM this board has.
// This on-device controller commissions one device at a time, so a small pool suffices.
#define CHIP_CONFIG_CONTROLLER_MAX_ACTIVE_DEVICES 2
```

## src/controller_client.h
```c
/*
 * ControllerClient — the on-device Matter commissioner singleton.
 *
 * Mirrors esp-matter's matter_controller_client (init + setup_commissioner)
 * onto connectedhomeip's own controller library. Owns the storage/keystore/
 * opcertstore/group-data objects, the DeviceControllerFactory wiring, the
 * ExampleOperationalCredentialsIssuer, and the DeviceCommissioner. See
 * the init order in main.cpp for the exact
 * ordered init sequence this implements.
 *
 * In plain English:
 * This file declares the "brain" of our smart-home hub. Matter is the
 * industry standard that lets smart devices from different brands work
 * together; the "commissioner" (also called the controller) is the piece
 * that actually adds new devices to your home and then controls them.
 * THIS firmware is that commissioner. This header lists everything the
 * commissioner owns (its secure storage, its cryptographic keys, its digital
 * "ID card" tools) and the handful of actions it can perform: start up,
 * set itself up, pair a new device, and remove a device. The .cpp file holds
 * the real logic; this file is just the "table of contents" / blueprint.
 */
#pragma once

// These #include lines pull in pieces of "connectedhomeip" (also called CHIP),
// the open-source code that implements Matter. (CHIP was Matter's old name.)
// Each header below gives us one building block: the device controller itself,
// the factory that wires everything together, the credential/certificate tools,
// on-chip storage, and cryptography helpers.
#include <controller/CHIPDeviceController.h>
#include <controller/CHIPDeviceControllerFactory.h>
#include <controller/AutoCommissioner.h>
#include <controller/ExampleOperationalCredentialsIssuer.h>
#include <credentials/GroupDataProviderImpl.h>
#include <credentials/PersistentStorageOpCertStore.h>
#include <crypto/PersistentStorageOperationalKeystore.h>
#include <crypto/PSASessionKeystore.h>
#include <include/platform/KvsPersistentStorageDelegate.h>
#include <lib/core/CHIPError.h>
#include <lib/core/DataModelTypes.h>
#include <lib/support/Span.h>

namespace nrf {
namespace controller {

// The one and only commissioner object for this firmware. It is a "singleton":
// there is exactly one instance for the whole program, reached via Instance().
// It holds the hub's identity and secure storage and runs every pairing.
class ControllerClient
{
public:
    // Returns the single shared ControllerClient. Everyone who needs the hub
    // calls this instead of creating their own copy.
    static ControllerClient & Instance();

    // Step 1 of startup: turn on all the plumbing the hub needs before it can
    // do anything — its on-chip storage (survives reboots), its secure key
    // storage, and the factory that builds the commissioner. Call this first.
    // The default arguments give this hub its own numeric identity: a Node ID
    // (its address on the network), a Fabric ID (which "home" it belongs to —
    // a fabric is the set of devices that trust each other under one owner),
    // and a network port to listen on.
    /// Step 1: build storage/keystore/groupdata + DeviceControllerFactory::Init.
    CHIP_ERROR Init(chip::NodeId localNodeId = 0x000000000001B2C3ULL, chip::FabricId fabricId = 1,
                    uint16_t udpListenPort = 5580);

    // Step 2 of startup: create the hub's own identity (its certificate / "ID
    // card"), load the tools that check whether a new device is genuine, and
    // build the "commissioner" object that actually runs pairings. It also
    // installs the shared fabric secret (IPK) used to protect group messages.
    // Call this after Init().
    /// Step 2: attestation + issuer + controller NOC chain + SetupCommissioner + IPK.
    CHIP_ERROR SetupCommissioner();

    // Pair a brand-new device using Bluetooth + Thread. This is the main way we
    // add a device: talk to it over short-range Bluetooth (BLE), prove it's
    // genuine, hand it the "network name + password" (the Thread dataset) so it
    // can join this home's low-power wireless mesh, then finish over Thread.
    // Arguments: which Node ID to give the new device, its secret setup passcode
    // (PIN from its QR/label), its discriminator (a number it broadcasts so we
    // pick the right nearby device), and the Thread credentials as raw bytes.
    /// `matter controller pairing ble-thread <node> <datasetHex> <pin> <disc>`
    CHIP_ERROR PairBleThread(chip::NodeId nodeId, uint32_t setupPasscode, uint16_t discriminator,
                             const uint8_t * datasetTlv, size_t datasetLen);

    // Pair a device from just its setup code (the "MT:..." QR-code string or the
    // typed manual code). The code carries the passcode and discriminator, so
    // the commissioner figures out the rest and discovers the device itself.
    /// `matter controller pairing code <node> <MT:.../manual>`
    CHIP_ERROR PairCode(chip::NodeId nodeId, const char * setupCode);

    // Remove a previously-paired device from this home (forget/reset it).
    CHIP_ERROR Unpair(chip::NodeId nodeId);

    // Hand out the underlying commissioner object so other code can issue lower-
    // level Matter calls (e.g. reading or controlling an already-paired device).
    chip::Controller::DeviceCommissioner & Commissioner() { return mCommissioner; }
    // True once Init() + SetupCommissioner() have completed successfully.
    bool IsInitialized() const { return mInitialized; }

    // True once we've successfully added at least one device to this home. It
    // gets flipped on when a pairing finishes (the code that watches a pairing
    // reports "OnCommissioningSuccess" — Matter's "the device is now fully set
    // up" signal). The hub can retry pairing on its own; that automatic retry
    // loop checks this so it knows when to stop trying.
    /// True once a node has been fully commissioned (set by the pairing delegate's
    /// OnCommissioningSuccess). Used by the auto-commission retry loop to stop.
    static bool IsCommissioned();

    // True while a pairing attempt is currently underway ("in flight" = started
    // but not yet finished). The automatic retry loop checks this so it doesn't
    // kick off a second pairing on top of one that's already running.
    /// True while a pairing/commissioning attempt is in flight. The retry loop uses
    /// this to avoid starting a second PairDevice on top of a live one.
    static bool IsPairingActive();

private:
    // Private constructor: nobody can build their own ControllerClient. The only
    // way to get one is Instance() — that's what makes this a singleton (exactly
    // one for the whole program). "= default" means "use the compiler's empty
    // default; we don't need any special setup here."
    ControllerClient() = default;

    // Have startup (Init + SetupCommissioner) finished yet? Guards against using
    // the hub before it's ready.
    bool mInitialized = false;
    // This hub's own numeric address on the network (its Node ID).
    chip::NodeId mLocalNodeId = 0;
    // Which "home" (fabric) this hub belongs to — the set of devices that trust
    // each other under one owner.
    chip::FabricId mFabricId  = 1;

    // Storage / crypto plumbing (must outlive the commissioner).
    // These five objects are the hub's secure foundation. They're listed here so
    // they stay alive for the whole program (the commissioner points at them, so
    // they must not disappear first — that's what "must outlive" means).
    // On-chip storage that survives reboots (KVS = key/value store): keeps keys,
    // certs, and config across power cycles.
    chip::KvsPersistentStorageDelegate mStorage;
    // Secure storage for the hub's own private crypto keys (its operational keys).
    chip::PersistentStorageOperationalKeystore mOpKeystore;
    // Storage for the operational certificates — the digital "ID cards" (NOCs)
    // that prove membership in this home's network.
    chip::Credentials::PersistentStorageOpCertStore mOpCertStore;
    // The chip's in-memory session cryptography (PSA = the chip's secure crypto
    // system): protects the live encrypted sessions with devices.
    chip::Crypto::PSASessionKeystore mSessionKeystore;
    // Keys/info for group (one-to-many / multicast) control of devices, plus the
    // shared fabric secret (IPK) that protects group messages.
    chip::Credentials::GroupDataProviderImpl mGroupDataProvider;

    // Controller objects.
    // The main commissioner: the object that actually runs pairings and controls
    // devices. Other code borrows it via Commissioner().
    chip::Controller::DeviceCommissioner mCommissioner;
    // The SDK's helper that can drive the step-by-step pairing sequence
    // automatically (connect, verify, hand over Thread credentials, finish) so
    // the steps don't have to be scripted by hand. (Declared here as part of the
    // commissioner's plumbing; how it's plugged in is set up in the .cpp file.)
    chip::Controller::AutoCommissioner mAutoCommissioner;
    // The tool that creates and signs the digital "ID cards" (NOCs) — for this
    // hub and for each new device. "Example" = the SDK's reference issuer, fine
    // for development.
    chip::Controller::ExampleOperationalCredentialsIssuer mOpCredsIssuer;
};

} // namespace controller
} // namespace nrf
```
